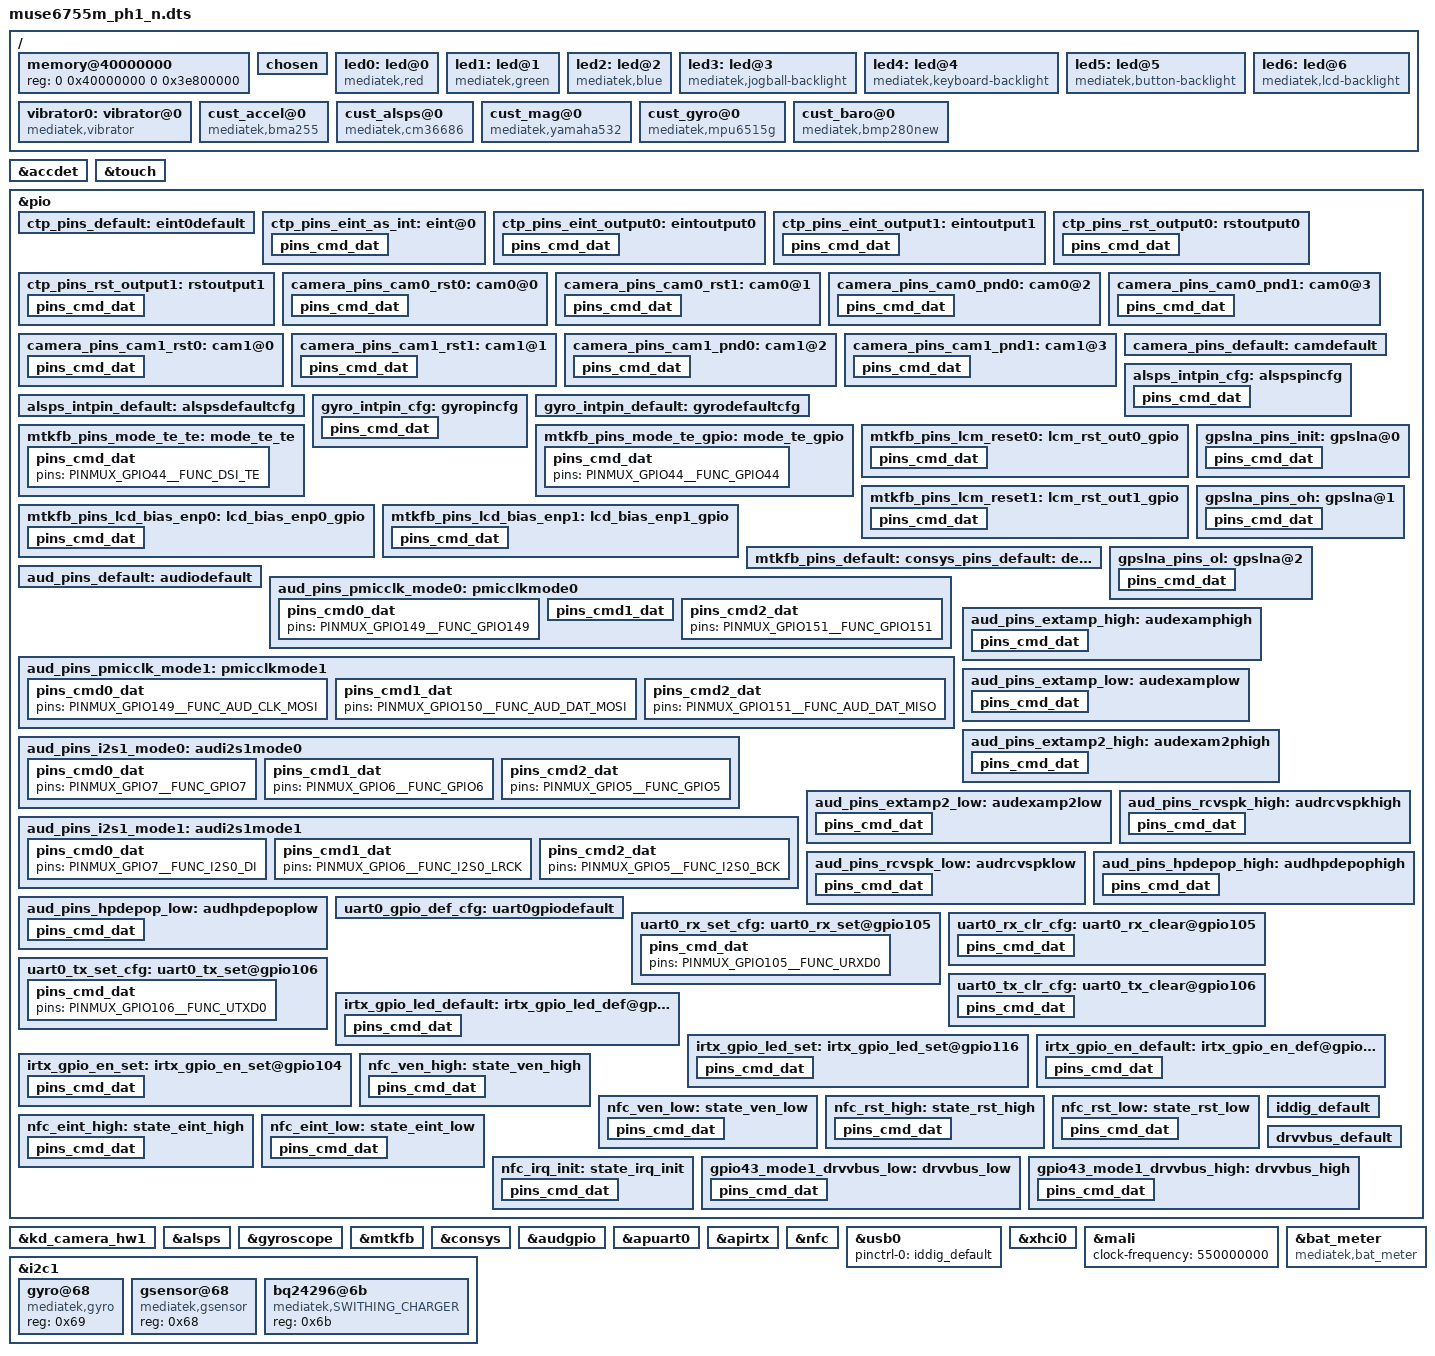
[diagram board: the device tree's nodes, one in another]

/dts-v1/;

#include "mt6755.dtsi"
#include "cust.dtsi"

/ {
	memory@40000000 {
		device_type = "memory";
		reg = <0 0x40000000 0 0x3e800000>;
	};
	/* chosen */
	chosen {
		bootargs = "console=tty0 console=ttyMT0,921600n1 root=/dev/ram initrd=0x44000000,0x4B434E loglevel=8";

		/* fpga may has no lk, we need to specify display info here */
		/* fb buffer is reserved using this dts by memory node above */
		atag,videolfb-fb_base_h = <0x0>;
		atag,videolfb-fb_base_l = <0x7E800000>;
		atag,videolfb-islcmfound = <1>;
		/* because no lk, so lcm is not inited */
		atag,videolfb-islcm_inited = <0>;
		atag,videolfb-fps= <6000>;
		atag,videolfb-vramSize= <0x01800000>;
		atag,videolfb-lcmname= "nt35695_fhd_dsi_cmd_truly_nt50358_drv";
	};
	led0:led@0 {
		compatible = "mediatek,red";
		led_mode = <0>;
		data = <1>;
		pwm_config = <0 0 0 0 0>;
	};
	led1:led@1 {
		compatible = "mediatek,green";
		led_mode = <0>;
		data = <1>;
		pwm_config = <0 0 0 0 0>;
	};
	led2:led@2 {
		compatible = "mediatek,blue";
		led_mode = <0>;
		data = <1>;
		pwm_config = <0 0 0 0 0>;
	};
	led3:led@3 {
		compatible = "mediatek,jogball-backlight";
		led_mode = <0>;
		data = <1>;
		pwm_config = <0 0 0 0 0>;
	};
	led4:led@4 {
		compatible = "mediatek,keyboard-backlight";
		led_mode = <0>;
		data = <1>;
		pwm_config = <0 0 0 0 0>;
	};
	led5:led@5 {
		compatible = "mediatek,button-backlight";
		led_mode = <0>;
		data = <1>;
		pwm_config = <0 0 0 0 0>;
	};
	led6:led@6 {
		compatible = "mediatek,lcd-backlight";
		led_mode = <4>;
		data = <1>;
		pwm_config = <0 0 0 0 0>;
	};
	vibrator0:vibrator@0 {
		compatible = "mediatek,vibrator";
		vib_timer = <25>;
		vib_limit = <9>;
		vib_vol= <5>;
	};
/*  start sensor */
	cust_accel@0 {
	compatible = "mediatek,bma255";
	reg = <0x11>;
	i2c_num	= <1>;
	i2c_addr = <0x11 0 0 0>;
	direction = <5>;
	power_id = <0xffff>;
	power_vol = <0>;
	firlen = <0>;
	is_batch_supported = <0>;
	};

	cust_alsps@0 {
		compatible		= "mediatek,cm36686";
		i2c_num			= <1>;
		i2c_addr		= <0x60 0 0 0>;
		polling_mode_ps		= <0>;
		polling_mode_als	= <1>;
		power_id		= <0xffff>;
		power_vol		= <0>;
/* Total has 15 level*/
		als_level	= <0 257 637 1027 2297 5588 6730 11301 20449 25768 31122 45552 57937 57937 57937>;
/*  Total has 16 range*/
		als_value	= <0 132 304 502 1004 2003 3006 5006 8004 10000 12000 16000 20000 20000 20000 20000>;
		ps_threshold_high	=  <70>;
		ps_threshold_low	=  <40>;
		is_batch_supported_ps	= <1>;
		is_batch_supported_als	= <1>;
	};

	cust_mag@0 {
	compatible			= "mediatek,yamaha532";
	i2c_num				= <1>;
	/* i2c_addr			= <0x0D 0 0 0>; */
	direction			= <0>;
	power_id			= <0xffff>;
	power_vol			= <0>;
	/* is_batch_supported		= <0>; */
	};

	cust_gyro@0 {
	compatible			= "mediatek,mpu6515g";
	i2c_num				= <1>;
	/* i2c_addr			= <0x68 0 0 0>; */
	direction			= <6>;
	power_id			= <0xffff>;
	power_vol			= <0>;
	firlen				= <0>;
	is_batch_supported		= <0>;
	};

	cust_baro@0 {
	compatible			= "mediatek,bmp280new";
	i2c_num				= <1>;
	/* i2c_addr			= <0x68 0 0 0>; */
	direction			= <0>;
	power_id			= <0xffff>;
	power_vol			= <0>;
	firlen				= <32>;
	is_batch_supported		= <0>;
	};
/* end sensor */
};
&accdet {
		accdet-mic-vol = <7>;
		headset-mode-setting = <0x500 0x500 1 0x3F0 0x800 0x800 0x200>;
		accdet-plugout-debounce = <20>;
		/*1:ACC mode, 2:low cost without in bias, 6:low cost with in bias*/
		accdet-mic-mode = <1>;
		/*0--MD_MAX--UP_MAX--DW_MAX*/
		headset-three-key-threshold = <0 80 220 500>;
		/*0--MD_MAX--VOICE_MAX--UP_MAX--DW_MAX*/
		headset-four-key-threshold = <0 58 121 192 450>;
};

/* TOUCH start */
&touch {
	tpd-resolution = <1080 1920>;
	use-tpd-button = <0>;
	tpd-key-num = <3>;
	tpd-key-local= <139 172 158 0>;
	tpd-key-dim-local = <90 883 100 40 230 883 100 40 370 883 100 40 0 0 0 0>;
	tpd-max-touch-num = <5>;
	tpd-filter-enable = <1>;
	tpd-filter-pixel-density = <146>;
	tpd-filter-custom-prameters = <0 0 0 0 0 0 0 0 0 0 0 0>;
	tpd-filter-custom-speed = <0 0 0>;
	pinctrl-names = "default", "state_eint_as_int", "state_eint_output0", "state_eint_output1",
		"state_rst_output0", "state_rst_output1";
	pinctrl-0 = <&ctp_pins_default>;
	pinctrl-1 = <&ctp_pins_eint_as_int>;
	pinctrl-2 = <&ctp_pins_eint_output0>;
	pinctrl-3 = <&ctp_pins_eint_output1>;
	pinctrl-4 = <&ctp_pins_rst_output0>;
	pinctrl-5 = <&ctp_pins_rst_output1>;
	status = "okay";
};
&pio {
	ctp_pins_default: eint0default {
	};
	ctp_pins_eint_as_int: eint@0 {
		pins_cmd_dat {
			pins = <PINMUX_GPIO1__FUNC_GPIO1>;
			slew-rate = <0>;
			bias-disable;
		};
	};
	ctp_pins_eint_output0: eintoutput0 {
		pins_cmd_dat {
			pins = <PINMUX_GPIO1__FUNC_GPIO1>;
			slew-rate = <1>;
			output-low;
		};
	};
	ctp_pins_eint_output1: eintoutput1 {
		pins_cmd_dat {
			pins = <PINMUX_GPIO1__FUNC_GPIO1>;
			slew-rate = <1>;
			output-high;
		};
	};
	ctp_pins_rst_output0: rstoutput0 {
		pins_cmd_dat {
			pins = <PINMUX_GPIO10__FUNC_GPIO10>;
			slew-rate = <1>;
			output-low;
		};
	};
	ctp_pins_rst_output1: rstoutput1 {
		pins_cmd_dat {
			pins = <PINMUX_GPIO10__FUNC_GPIO10>;
			slew-rate = <1>;
			output-high;
		};
	};
};
/* TOUCH end */

/* CAMERA GPIO standardization */
&pio {
	camera_pins_cam0_rst0: cam0@0 {
	    pins_cmd_dat {
			pins = <PINMUX_GPIO110__FUNC_GPIO110>;
			slew-rate = <1>; /*direction 0:in, 1:out*/
			output-low;/*direction out used only. output_low or high*/
		};
	};
	camera_pins_cam0_rst1: cam0@1 {
	    pins_cmd_dat {
			pins = <PINMUX_GPIO110__FUNC_GPIO110>;
			slew-rate = <1>;
			output-high;
		};
	};
	camera_pins_cam0_pnd0: cam0@2 {
	    pins_cmd_dat {
			pins = <PINMUX_GPIO107__FUNC_GPIO107>;
			slew-rate = <1>;
			output-low;
		};
	};
	camera_pins_cam0_pnd1: cam0@3 {
	    pins_cmd_dat {
			pins = <PINMUX_GPIO107__FUNC_GPIO107>;
			slew-rate = <1>;
			output-high;
		};
	};
	camera_pins_cam1_rst0: cam1@0 {
	    pins_cmd_dat {
			pins = <PINMUX_GPIO111__FUNC_GPIO111>;
			slew-rate = <1>; /*direction 0:in, 1:out*/
			output-low;/*direction out used only. output_low or high*/
		};
	};
	camera_pins_cam1_rst1: cam1@1 {
	    pins_cmd_dat {
			pins = <PINMUX_GPIO111__FUNC_GPIO111>;
			slew-rate = <1>;
			output-high;
		};
	};
	camera_pins_cam1_pnd0: cam1@2 {
	    pins_cmd_dat {
			pins = <PINMUX_GPIO108__FUNC_GPIO108>;
			slew-rate = <1>;
			output-low;
		};
	};
	camera_pins_cam1_pnd1: cam1@3 {
	    pins_cmd_dat {
			pins = <PINMUX_GPIO108__FUNC_GPIO108>;
			slew-rate = <1>;
			output-high;
		};
	};
	/*camera_pins_cam_ldo_vcama_0: cam@vcama0 {
	};
	camera_pins_cam_ldo_vcama_1: cam@vcama1 {
	};*/
	camera_pins_default: camdefault {
	};

};

&kd_camera_hw1 {
	pinctrl-names = "default",
			"cam0_rst0", "cam0_rst1", "cam0_pnd0", "cam0_pnd1",
			"cam1_rst0", "cam1_rst1", "cam1_pnd0", "cam1_pnd1";
			/*"cam2_rst0", "cam2_rst1", "cam2_pnd0", "cam2_pnd1",
			"cam_ldo_vcama_0", "cam_ldo_vcama_1";*/
	pinctrl-0 = <&camera_pins_default>;
	pinctrl-1 = <&camera_pins_cam0_rst0>;
	pinctrl-2 = <&camera_pins_cam0_rst1>;
	pinctrl-3 = <&camera_pins_cam0_pnd0>;
	pinctrl-4 = <&camera_pins_cam0_pnd1>;
	pinctrl-5 = <&camera_pins_cam1_rst0>;
	pinctrl-6 = <&camera_pins_cam1_rst1>;
	pinctrl-7 = <&camera_pins_cam1_pnd0>;
	pinctrl-8 = <&camera_pins_cam1_pnd1>;
	/* for main2 */
	/*pinctrl-9 = <&camera_pins_cam2_rst0>;
	pinctrl-10 = <&camera_pins_cam2_rst1>;
	pinctrl-11 = <&camera_pins_cam2_pnd0>;
	pinctrl-12 = <&camera_pins_cam2_pnd1>;*/
	/* for ldo control by gpio */
	/*pinctrl-13 = <&camera_pins_cam_ldo_vcama_0>;
	pinctrl-14 = <&camera_pins_cam_ldo_vcama_1>;*/
	status = "okay";

};
/* CAMERA GPIO end */

&pio {
	alsps_intpin_cfg: alspspincfg {

		pins_cmd_dat {
			pins = <PINMUX_GPIO6__FUNC_GPIO6>;
			slew-rate = <0>;
			bias-pull-up = <00>;
		};
	};

	alsps_intpin_default: alspsdefaultcfg {

	};

	gyro_intpin_cfg: gyropincfg {

		pins_cmd_dat {
			pins = <PINMUX_GPIO4__FUNC_GPIO4>;
			slew-rate = <0>;
			bias-pull-down = <00>;
		};
	};

	gyro_intpin_default: gyrodefaultcfg {

	};
};

&alsps {
	pinctrl-names = "pin_default", "pin_cfg";
	pinctrl-0 = <&alsps_intpin_default>;
	pinctrl-1 = <&alsps_intpin_cfg>;
	status = "okay";
};

&gyroscope {
	pinctrl-names = "pin_default", "pin_cfg";
	pinctrl-0 = <&gyro_intpin_default>;
	pinctrl-1 = <&gyro_intpin_cfg>;
	status = "okay";
};

/* DISPSYS GPIO standardization */
&pio {

	mtkfb_pins_mode_te_gpio: mode_te_gpio {
		pins_cmd_dat {
			pins = <PINMUX_GPIO44__FUNC_GPIO44>;
		};
	};

	mtkfb_pins_mode_te_te: mode_te_te {
		pins_cmd_dat {
			pins = <PINMUX_GPIO44__FUNC_DSI_TE>;
		};
	};

	mtkfb_pins_lcm_reset0: lcm_rst_out0_gpio {
		pins_cmd_dat {
			pins = <PINMUX_GPIO158__FUNC_LCM_RST>;
			slew-rate = <1>;
			output-low;
		};
	};

	mtkfb_pins_lcm_reset1: lcm_rst_out1_gpio {
		pins_cmd_dat {
			pins = <PINMUX_GPIO158__FUNC_LCM_RST>;
			slew-rate = <1>;
			output-high;
		};
	};

	mtkfb_pins_lcd_bias_enp0: lcd_bias_enp0_gpio {
		pins_cmd_dat {
			pins = <PINMUX_GPIO12__FUNC_GPIO12>;
			slew-rate = <1>;
			output-low;
		};
	};

	mtkfb_pins_lcd_bias_enp1: lcd_bias_enp1_gpio {
		pins_cmd_dat {
			pins = <PINMUX_GPIO12__FUNC_GPIO12>;
			slew-rate = <1>;
			output-high;
		};
	};

	mtkfb_pins_default: default {
	};
};

&mtkfb {
	pinctrl-names = "default", "mode_te_gpio", "mode_te_te", "lcm_rst_out0_gpio",
	"lcm_rst_out1_gpio", "lcd_bias_enp0_gpio", "lcd_bias_enp1_gpio";
	pinctrl-0 = <&mtkfb_pins_default>;
	pinctrl-1 = <&mtkfb_pins_mode_te_gpio>;
	pinctrl-2 = <&mtkfb_pins_mode_te_te>;
	pinctrl-3 = <&mtkfb_pins_lcm_reset0>;
	pinctrl-4 = <&mtkfb_pins_lcm_reset1>;
	pinctrl-5 = <&mtkfb_pins_lcd_bias_enp0>;
	pinctrl-6 = <&mtkfb_pins_lcd_bias_enp1>;
	status = "okay";
};/* DISPSYS GPIO standardization end */

/* CONSYS GPIO standardization */
&pio {
	consys_pins_default: default {
	};

	gpslna_pins_init: gpslna@0 {
		pins_cmd_dat {
			pins = <PINMUX_GPIO114__FUNC_GPIO114>;
			slew-rate = <0>;
			bias-disable;
			output-low;
		};
	};

	gpslna_pins_oh: gpslna@1 {
		pins_cmd_dat {
			pins = <PINMUX_GPIO114__FUNC_GPIO114>;
			slew-rate = <1>;
			output-high;
		};
	};

	gpslna_pins_ol: gpslna@2 {
		pins_cmd_dat {
			pins = <PINMUX_GPIO114__FUNC_GPIO114>;
			slew-rate = <1>;
			output-low;
		};
	};
};

&consys {
	pinctrl-names = "default", "gps_lna_state_init", "gps_lna_state_oh", "gps_lna_state_ol";
	pinctrl-0 = <&consys_pins_default>;
	pinctrl-1 = <&gpslna_pins_init>;
	pinctrl-2 = <&gpslna_pins_oh>;
	pinctrl-3 = <&gpslna_pins_ol>;
	status = "okay";
};
/* CONSYS end */

/* AUDIO GPIO standardization */
&audgpio {
	pinctrl-names = "default", "audpmicclk-mode0", "audpmicclk-mode1",
		"audi2s1-mode0", "audi2s1-mode1", "extamp-pullhigh", "extamp-pulllow",
		"extamp2-pullhigh", "extamp2-pulllow", "rcvspk-pullhigh",
		"rcvspk-pulllow","hpdepop-pullhigh","hpdepop-pulllow";
	pinctrl-0 = <&aud_pins_default>;
	pinctrl-1 = <&aud_pins_pmicclk_mode0>;
	pinctrl-2 = <&aud_pins_pmicclk_mode1>;
	pinctrl-3 = <&aud_pins_i2s1_mode0>;
	pinctrl-4 = <&aud_pins_i2s1_mode1>;
	pinctrl-5 = <&aud_pins_extamp_high>;
	pinctrl-6 = <&aud_pins_extamp_low>;
	pinctrl-7 = <&aud_pins_extamp2_high>;
	pinctrl-8 = <&aud_pins_extamp2_low>;
	pinctrl-9 = <&aud_pins_rcvspk_high>;
	pinctrl-10 = <&aud_pins_rcvspk_low>;
	pinctrl-11 = <&aud_pins_hpdepop_high>;
	pinctrl-12 = <&aud_pins_hpdepop_low>;
	status = "okay";
};

&pio {
	aud_pins_default: audiodefault {
	};

	aud_pins_pmicclk_mode0: pmicclkmode0 {
		pins_cmd0_dat {
			pins = <PINMUX_GPIO149__FUNC_GPIO149>;
		};
		pins_cmd1_dat {
			pins = <PINMUX_GPIO150__FUNC_GPIO150>;
			slew-rate = <0>;
			bias-pull-up = <00>;
		};
		pins_cmd2_dat {
			pins = <PINMUX_GPIO151__FUNC_GPIO151>;
		};
	};

	aud_pins_pmicclk_mode1: pmicclkmode1 {
		pins_cmd0_dat {
			pins = <PINMUX_GPIO149__FUNC_AUD_CLK_MOSI>;
		};
		pins_cmd1_dat {
			pins = <PINMUX_GPIO150__FUNC_AUD_DAT_MOSI>;
		};
		pins_cmd2_dat {
			pins = <PINMUX_GPIO151__FUNC_AUD_DAT_MISO>;
		};
	};

	aud_pins_i2s1_mode0: audi2s1mode0 {
		pins_cmd0_dat {
			pins = <PINMUX_GPIO7__FUNC_GPIO7>;
		};
		pins_cmd1_dat {
			pins = <PINMUX_GPIO6__FUNC_GPIO6>;
		};
		pins_cmd2_dat {
			pins = <PINMUX_GPIO5__FUNC_GPIO5>;
		};
	};

	aud_pins_i2s1_mode1: audi2s1mode1 {
		pins_cmd0_dat {
			pins = <PINMUX_GPIO7__FUNC_I2S0_DI>;
		};
		pins_cmd1_dat {
			pins = <PINMUX_GPIO6__FUNC_I2S0_LRCK>;
		};
		pins_cmd2_dat {
			pins = <PINMUX_GPIO5__FUNC_I2S0_BCK>;
		};
	};

	aud_pins_extamp_high: audexamphigh {
		pins_cmd_dat {
			pins = <PINMUX_GPIO115__FUNC_GPIO115>;
			slew-rate = <1>;
			output-high;
		};
	};

	aud_pins_extamp_low: audexamplow {
		pins_cmd_dat {
			pins = <PINMUX_GPIO115__FUNC_GPIO115>;
			slew-rate = <1>;
			output-low;
		};
	};

	aud_pins_extamp2_high: audexam2phigh {
		pins_cmd_dat {
			pins = <PINMUX_GPIO54__FUNC_GPIO54>;
			slew-rate = <1>;
			output-high;
		};
	};
	aud_pins_extamp2_low: audexamp2low {
		pins_cmd_dat {
			pins = <PINMUX_GPIO54__FUNC_GPIO54>;
			slew-rate = <1>;
			output-low;
		};
	};

	aud_pins_rcvspk_high: audrcvspkhigh {
		pins_cmd_dat {
			pins = <PINMUX_GPIO120__FUNC_GPIO120>;
			slew-rate = <1>;
			output-high;
		};
	};

	aud_pins_rcvspk_low: audrcvspklow {
		pins_cmd_dat {
			pins = <PINMUX_GPIO120__FUNC_GPIO120>;
			slew-rate = <1>;
			output-low;
		};
	};

	aud_pins_hpdepop_high: audhpdepophigh {
		pins_cmd_dat {
			pins = <PINMUX_GPIO24__FUNC_GPIO24>;
			slew-rate = <1>;
			output-high;
		};
	};

	aud_pins_hpdepop_low: audhpdepoplow {
		pins_cmd_dat {
			pins = <PINMUX_GPIO24__FUNC_GPIO24>;
			slew-rate = <1>;
			output-low;
		};
	};
};
/* AUDIO end */

/* UART GPIO */
&apuart0 {
	pinctrl-names = "uart0_gpio_default",
			"uart0_rx_set",
			"uart0_rx_clear",
			"uart0_tx_set",
			"uart0_tx_clear";
	pinctrl-0 = <&uart0_gpio_def_cfg>;
	pinctrl-1 = <&uart0_rx_set_cfg>;
	pinctrl-2 = <&uart0_rx_clr_cfg>;
	pinctrl-3 = <&uart0_tx_set_cfg>;
	pinctrl-4 = <&uart0_tx_clr_cfg>;
	status = "okay";
};

&pio {
	/* UART GPIO Settings - Start */
	/* UART0: rx set, rx clear, tx clear, tx clear*/
	uart0_gpio_def_cfg:uart0gpiodefault {

	};
	uart0_rx_set_cfg:uart0_rx_set@gpio105 {
		pins_cmd_dat {
			pins = <PINMUX_GPIO105__FUNC_URXD0>;
		};
	};
	uart0_rx_clr_cfg:uart0_rx_clear@gpio105  {
		pins_cmd_dat {
			pins = <PINMUX_GPIO105__FUNC_GPIO105>;
			slew-rate = <1>;
			output-high;
		};
	};
	uart0_tx_set_cfg:uart0_tx_set@gpio106  {
		pins_cmd_dat {
			pins = <PINMUX_GPIO106__FUNC_UTXD0>;
		};
	};
	uart0_tx_clr_cfg:uart0_tx_clear@gpio106  {
		pins_cmd_dat {
			pins = <PINMUX_GPIO106__FUNC_GPIO106>;
			slew-rate = <1>;
			output-high;
		};
	};
};/* UART GPIO end */

/* IRTX GPIO end */
&apirtx {
	pinctrl-names = "irtx_gpio_led_default",
			"irtx_gpio_led_set",
			"irtx_gpio_en_default",
			"irtx_gpio_en_set";

	pinctrl-0 = <&irtx_gpio_led_default>;
	pinctrl-1 = <&irtx_gpio_led_set>;
	pinctrl-2 = <&irtx_gpio_en_default>;
	pinctrl-3 = <&irtx_gpio_en_set>;
	status = "okay";
};
&pio {
	/* IRTX GPIO Settings -Start */
	/* default: GPIO0, output, high */
	irtx_gpio_led_default:irtx_gpio_led_def@gpio116 {
		pins_cmd_dat {
			pins = <PINMUX_GPIO116__FUNC_GPIO116>;
			slew-rate = <1>;
			bias-disable;
			output-low;
			input-schmitt-enable = <0>;
		};
	};

	irtx_gpio_led_set:irtx_gpio_led_set@gpio116 {
		pins_cmd_dat {
			pins = <PINMUX_GPIO116__FUNC_GPIO116>;
			slew-rate = <1>;
			output-high;
		};
	};

	irtx_gpio_en_default:irtx_gpio_en_def@gpio104 {
		pins_cmd_dat {
			pins = <PINMUX_GPIO104__FUNC_GPIO104>;
			slew-rate = <1>;
			bias-disable;
			output-low;
			input-schmitt-enable = <0>;
		};
	};

	irtx_gpio_en_set:irtx_gpio_en_set@gpio104 {
		pins_cmd_dat {
			pins = <PINMUX_GPIO104__FUNC_GPIO104>;
			slew-rate = <1>;
			output-high;
		};
	};


}; /* IRTX GPIO Settings -End */

/* NFC GPIO standardization */
&pio {
	nfc_default: default {

	};

	nfc_ven_high: state_ven_high {
		pins_cmd_dat {
			pins = <PINMUX_GPIO28__FUNC_GPIO28>;
			slew-rate = <1>;
			output-high;
		};
	};

	nfc_ven_low: state_ven_low {
		pins_cmd_dat {
			pins = <PINMUX_GPIO28__FUNC_GPIO28>;
			slew-rate = <1>;
			output-low;
		};
	};

	nfc_rst_high: state_rst_high {
		pins_cmd_dat {
			pins = <PINMUX_GPIO25__FUNC_GPIO25>;
			slew-rate = <1>;
			output-high;
		};
	};

	nfc_rst_low: state_rst_low {
		pins_cmd_dat {
			pins = <PINMUX_GPIO25__FUNC_GPIO25>;
			slew-rate = <1>;
			output-low;
		};
	};

	nfc_eint_high: state_eint_high {
		pins_cmd_dat {
			pins = <PINMUX_GPIO27__FUNC_GPIO27>;
			slew-rate = <1>;
			output-high;
		};
	};

	nfc_eint_low: state_eint_low {
		pins_cmd_dat {
			pins = <PINMUX_GPIO27__FUNC_GPIO27>;
			slew-rate = <1>;
			output-low;
		};
	};

	nfc_irq_init: state_irq_init {
		pins_cmd_dat {
			pins = <PINMUX_GPIO26__FUNC_GPIO26>;
			slew-rate = <0>;
			bias-pull-down = <00>;
		};
	};
};

&nfc {
	pinctrl-names = "default", "ven_high", "ven_low", "rst_high", "rst_low", "eint_high", "eint_low", "irq_init";
	pinctrl-0 = <&nfc_default>;
	pinctrl-1 = <&nfc_ven_high>;
	pinctrl-2 = <&nfc_ven_low>;
	pinctrl-3 = <&nfc_rst_high>;
	pinctrl-4 = <&nfc_rst_low>;
	pinctrl-5 = <&nfc_eint_high>;
	pinctrl-6 = <&nfc_eint_low>;
	pinctrl-7 = <&nfc_irq_init>;
	status = "okay";
};
/* NFC end */




&pio {
	iddig_default: iddig_default {
	};

/*
	gpio42_mode1_iddig: iddig_init {
		pins_cmd_dat {
			pins = <PINMUX_GPIO42__FUNC_IDDIG>;
			slew-rate = <0>;
			bias-pull-up = <00>;
		};
	};
*/
};

&pio {
	drvvbus_default: drvvbus_default {
	};

	gpio43_mode1_drvvbus_low: drvvbus_low {
		pins_cmd_dat {
			pins = <PINMUX_GPIO43__FUNC_USB_DRVVBUS>;
			slew-rate = <1>;
			output-low;
		};
	};

	gpio43_mode1_drvvbus_high: drvvbus_high {
		pins_cmd_dat {
			pins = <PINMUX_GPIO43__FUNC_USB_DRVVBUS>;
			slew-rate = <1>;
			output-high;
		};
	};
};

&usb0 {
	pinctrl-names = "iddig_default", "iddig_init";
	pinctrl-0 = <&iddig_default>;
/*	pinctrl-1 = <&gpio42_mode1_iddig>; */
	status = "okay";
};

&xhci0 {
	pinctrl-names = "drvvbus_default", "drvvbus_low", "drvvbus_high";
	pinctrl-0 = <&drvvbus_default>;
	pinctrl-1 = <&gpio43_mode1_drvvbus_low>;
	pinctrl-2 = <&gpio43_mode1_drvvbus_high>;
	status = "okay";
};

&i2c1 {

	gyro@68 {
		compatible = "mediatek,gyro";
		reg = <0x69>;
		status = "okay";
	};

	gsensor@68 {
		compatible = "mediatek,gsensor";
		reg = <0x68>;
		status = "okay";
	};

	bq24296@6b {
		compatible = "mediatek,SWITHING_CHARGER";
		reg = <0x6b>;
		status = "okay";
	};
};

&mali {
	clock-frequency = <550000000>;
};

&bat_meter {
compatible = "mediatek,bat_meter";
/* cust_charging.h */
/* stop charging while in talking mode */
stop_charging_in_takling = <1 >;
talking_recharge_voltage = <3800 >;
talking_sync_time = <60 >;

/* Battery Temperature Protection */
mtk_temperature_recharge_support = <1 >;
max_charge_temperature = <50 >;
max_charge_temperature_minus_x_degree = <47 >;
min_charge_temperature = <0 >;
min_charge_temperature_plus_x_degree = <6 >;
err_charge_temperature = <0xff >;

/* Linear Charging Threshold */
v_pre2cc_thres = <3400 >;	/* unit: mV */
v_cc2topoff_thres = <4050 >;
recharging_voltage = <4110 >;
charging_full_current = <100 >;	/* unit: mA */

/* Charging Current Setting */
config_usb_if = <0 >;
usb_charger_current_suspend = <0 >;	/* Unit: 0.01 mA */
usb_charger_current_unconfigured = <7000 >;	/* Unit: 0.01 mA */
usb_charger_current_configured = <50000 >;	/* Unit: 0.01 mA */
usb_charger_current = <50000 >;	/* Unit: 0.01 mA */
ac_charger_current = <80000 >;	/* Unit: 0.01 mA */
non_std_ac_charger_current = <50000 >;	/* Unit: 0.01 mA */
charging_host_charger_current = <65000 >;	/* Unit: 0.01 mA */
apple_0_5a_charger_current = <50000 >;	/* Unit: 0.01 mA */
apple_1_0a_charger_current = <65000 >;	/* Unit: 0.01 mA */
apple_2_1a_charger_current = <80000 >;	/* Unit: 0.01 mA */


/* charger error check */
bat_low_temp_protect_enable = <0 >;
v_charger_enable = <0 >;	/* 1:on , 0:off */
v_charger_max = <6500 >;	/* unit: mV */
v_charger_min = <4400 >;

/*  Tracking TIME */
onehundred_percent_tracking_time = <10 >;	/* Unit: second */
npercent_tracking_time = <20 >;	/* Unit: second */
sync_to_real_tracking_time = <60 >;	/* Unit: second */
v_0percent_tracking = <3450 >;	/* Unit: mV */

/* High battery support */
high_battery_voltage_support = <0 >;

/* cust_battery_meter.h */
hw_fg_force_use_sw_ocv = <0 >;
/* ADC resistor  */
r_bat_sense = <4 >;
r_i_sense = <4 >;
r_charger_1 = <330 >;
r_charger_2 = <39 >;
temperature_t0 = <110 >;
temperature_t1 = <0 >;
temperature_t2 = <25 >;
temperature_t3 = <50 >;
temperature_t = <255 >;	/* this should be fixed, never change the value */
fg_meter_resistance = <0 >;

/* Qmax for 0mA */
q_max_pos_50 = <3003 >;
q_max_pos_25 = <2838 >;
q_max_pos_0 = <2723 >;
q_max_neg_10 = <2498 >;
/* Qmax for 400mA, said high current */
q_max_pos_50_h_current = <2991 >;
q_max_pos_25_h_current = <2818 >;
q_max_pos_0_h_current = <2476 >;
q_max_neg_10_h_current = <1633 >;
/* Discharge percentage, 1: D5, 0: D2 */
oam_d5 = <1 >;

change_tracking_point = <1 >;
/* SW OCV tracking setting */
cust_tracking_point = <0 >;
cust_r_sense = <56 >;
cust_hw_cc = <0 >;
aging_tuning_value = <103 >;
cust_r_fg_offset = <0 >;
ocv_board_compesate = <0 >;
r_fg_board_base = <1000 >;
r_fg_board_slope = <1000 >;
car_tune_value = <100 >;

/* HW Fuel gague  */
current_detect_r_fg = <10 >;	/* Unit: mA */
minerroroffset = <1000 >;
fg_vbat_average_size = <18 >;
r_fg_value = <10 >;	/* Unit: mOhm */

/* HW Fuel gague 2.0*/
difference_hwocv_rtc = <30 >;
difference_hwocv_swocv = <10>;
difference_swocv_rtc = <10>;

difference_hwocv_vbat = <30>;
difference_vbat_rtc = <30>;
difference_swocv_rtc_pos = <15>;

max_swocv = <3>;

difference_voltage_update = <20>;
aging1_load_soc = <70>;
aging1_update_soc = <30>;
batterypseudo100 = <95>;
batterypseudo1 = <6>;

q_max_by_sys = <1>;			/*8. qmax variant by system drop voltage.*/
q_max_sys_voltage = <3350>;
shutdown_gauge0 = <0>;
shutdown_gauge1_xmins = <0>;
shutdown_gauge1_mins = <60>;

shutdown_system_voltage = <3400>;
charge_tracking_time = <60>;
discharge_tracking_time = <10>;

recharge_tolerance = <10>;

/* SW Fuel Gauge */
max_hwocv = <5 >;
max_vbat = <90 >;



/* HW Fuel gague 1.0*/
cust_poweron_delta_capacity_tolrance = <40 >;
cust_poweron_low_capacity_tolrance = <5 >;
cust_poweron_max_vbat_tolrance = <90 >;
cust_poweron_delta_vbat_tolrance = <30 >;
cust_poweron_delta_hw_sw_ocv_capacity_tolrance = <10 >;

/* Fixed battery temperature */
fixed_tbat_25 = <0 >;
/* Dynamic change wake up period of battery thread when suspend */
vbat_normal_wakeup = <3600 >;	/* Unit: mV */
vbat_low_power_wakeup = <3500 >;	/* Unit: mV */
normal_wakeup_period = <5400 >;	/* Unit: second */
low_power_wakeup_period = <300 >;	/* Unit: second */
close_poweroff_wakeup_period = <30 >;	/* Unit: second */

init_soc_by_sw_soc = <1 >;
sync_ui_soc_imm =<0>;
mtk_enable_aging_algorithm = <1>;
md_sleep_current_check = <1>;
q_max_by_current = <0>;

/* SOC track to SWOCV */
cust_tracking_gap = <15 >;	/* start tracking gap */
cust_trackingoffset = <0 >;	/* force offset to shift soc to 0 */
cust_trackingen = <0 >;	/* 0:disable, 1:enable */

/* keep min uisoc until voltage less than shutdown voltage */
cust_min_uisoc_percentage = <1 >;

rbat_pull_up_r = <62000 >;
rbat_pull_up_volt = <1800 >;

batt_temperature_table_size = <17 >;
batt_temperature_table = <
	(-20) 738931
	(-15) 547472
	(-10) 409600
	(-5) 309299
	0 235622
	5 181001
	10 140153
	15 109349
	20 85934
	25 68000 30 54165 35 43418 40 35014 45 28400 50 23164 55 17733 60 15656 >;

/* PH1_ZCV Table_ EAC63158401 4.4 V 3000mAH  V1.0_cut off 3.3V */
battery_profile_t0_size = <69 >;
battery_profile_t0 = <0 4357
	2 4329
	4 4304
	6 4280
	8 4258
	10 4236
	12 4214
	14 4192
	16 4170
	18 4148
	20 4124
	22 4099
	24 4075
	26 4052
	28 4032
	30 4012
	32 3992
	34 3972
	36 3954
	38 3936
	40 3916
	42 3898
	44 3879
	46 3864
	48 3849
	50 3837
	52 3827
	54 3819
	56 3811
	58 3804
	60 3799
	62 3795
	64 3790
	66 3788
	68 3783
	70 3779
	72 3773
	74 3767
	76 3759
	78 3750
	80 3740
	82 3729
	84 3718
	86 3707
	88 3697
	90 3687
	92 3675
	94 3658
	96 3631
	97 3614
	97 3603
	98 3592
	98 3582
	99 3572
	99 3561
	99 3549
	99 3539
	100 3528
	100 3518
	100 3509
	100 3509
	100 3509
	100 3509
	100 3509
	100 3509
	100 3509
	100 3509
	100 3509
	100 3300 >;
battery_profile_t1_size = <69 >;
battery_profile_t1 = <0 4384
	2 4358
	4 4332
	5 4300
	7 4269
	9 4240
	11 4213
	13 4187
	15 4164
	16 4141
	18 4118
	20 4098
	22 4077
	24 4058
	26 4038
	27 4019
	29 4000
	31 3984
	33 3968
	35 3952
	37 3934
	38 3916
	40 3898
	42 3881
	44 3867
	46 3855
	48 3845
	49 3836
	51 3828
	53 3820
	55 3813
	57 3807
	59 3800
	60 3794
	62 3790
	64 3786
	66 3782
	68 3779
	70 3775
	71 3771
	73 3766
	75 3760
	77 3753
	79 3745
	80 3735
	82 3723
	84 3711
	86 3700
	88 3692
	90 3685
	91 3676
	93 3666
	95 3642
	97 3586
	98 3540
	98 3512
	99 3488
	99 3468
	99 3451
	99 3435
	99 3421
	99 3408
	100 3396
	100 3386
	100 3375
	100 3366
	100 3357
	100 3348
	100 3300 >;
battery_profile_t2_size = <69 >;
battery_profile_t2 = <0 4392
	2 4372
	4 4355
	5 4336
	7 4317
	9 4297
	11 4278
	12 4258
	14 4239
	16 4218
	18 4198
	19 4178
	21 4158
	23 4139
	25 4120
	26 4101
	28 4084
	30 4067
	32 4049
	33 4032
	35 4015
	37 3999
	39 3982
	40 3965
	42 3944
	44 3923
	46 3905
	47 3890
	49 3878
	51 3868
	53 3857
	54 3849
	56 3839
	58 3831
	60 3824
	62 3817
	63 3810
	65 3804
	67 3798
	69 3792
	70 3787
	72 3781
	74 3775
	76 3771
	77 3762
	79 3753
	81 3745
	83 3733
	84 3719
	86 3703
	88 3692
	90 3689
	91 3688
	93 3686
	95 3680
	97 3622
	98 3509
	100 3279
	100 3058
	100 3005
	100 2983
	100 2968
	100 2956
	100 2950
	100 2941
	100 2941
	100 2938
	100 2933
	100 3400 >;
battery_profile_t3_size = <69 >;
battery_profile_t3 = <0 4395
	2 4373
	3 4355
	5 4337
	7 4318
	8 4299
	10 4279
	12 4260
	13 4239
	15 4220
	17 4200
	18 4180
	20 4161
	22 4142
	23 4123
	25 4105
	27 4087
	28 4070
	30 4052
	32 4036
	33 4020
	35 4004
	36 3990
	38 3976
	40 3963
	41 3949
	43 3936
	45 3920
	46 3896
	48 3877
	50 3865
	51 3854
	53 3845
	55 3836
	56 3828
	58 3821
	60 3814
	61 3807
	63 3802
	65 3796
	66 3790
	68 3786
	70 3782
	71 3775
	73 3765
	75 3755
	76 3749
	78 3742
	80 3734
	81 3728
	83 3720
	85 3705
	86 3693
	88 3676
	90 3675
	91 3673
	93 3670
	95 3667
	96 3628
	98 3536
	100 3382
	100 3108
	100 3060
	100 3034
	100 3013
	100 2998
	100 2983
	100 2972
	100 3400 >;

r_profile_t0_size = <69 >;
r_profile_t0 = <618 4357
	618 4329
	640 4304
	650 4280
	663 4258
	670 4236
	678 4214
	688 4192
	693 4170
	708 4148
	725 4124
	753 4099
	788 4075
	823 4052
	860 4032
	898 4012
	935 3992
	975 3972
	1025 3954
	1068 3936
	1108 3916
	1148 3898
	1153 3879
	1155 3864
	1153 3849
	1153 3837
	1158 3827
	1165 3819
	1165 3811
	1175 3804
	1183 3799
	1198 3795
	1208 3790
	1225 3788
	1240 3783
	1265 3779
	1288 3773
	1313 3767
	1335 3759
	1363 3750
	1395 3740
	1433 3729
	1475 3718
	1533 3707
	1598 3697
	1678 3687
	1773 3675
	1890 3658
	2025 3631
	2038 3614
	2010 3603
	1983 3592
	1958 3582
	1933 3572
	1910 3561
	1880 3549
	1850 3539
	1825 3528
	1803 3518
	1778 3509
	1778 3509
	1778 3509
	1778 3509
	1778 3509
	1778 3509
	1778 3509
	1778 3509
	1778 3509
	1255 3300 >;
r_profile_t1_size = <69 >;
r_profile_t1 = <300 4384
	300 4358
	313 4332
	325 4300
	350 4269
	375 4240
	395 4213
	420 4187
	443 4164
	465 4141
	485 4118
	510 4098
	530 4077
	553 4058
	565 4038
	578 4019
	583 4000
	593 3984
	593 3968
	595 3952
	585 3934
	583 3916
	573 3898
	563 3881
	563 3867
	563 3855
	568 3845
	568 3836
	570 3828
	578 3820
	580 3813
	588 3807
	588 3800
	595 3794
	600 3790
	605 3786
	613 3782
	620 3779
	628 3775
	638 3771
	648 3766
	660 3760
	673	3753
	688	3745
	705 3735
	723 3723
	745 3711
	775 3700
	813 3692
	880 3685
	975 3676
	1120 3666
	1345 3642
	1705 3586
	1853 3540
	1783 3512
	1725 3488
	1680 3468
	1630 3451
	1610 3435
	1570 3421
	1545 3408
	1495 3396
	1483 3386
	1440 3375
	1425 3366
	1393 3357
	1395 3348
	1290 3300 >;
r_profile_t2_size = <69 >;
r_profile_t2 = <155 4392
	155 4372
	158 4355
	158 4336
	158 4317
	155 4297
	160 4278
	163 4258
	165 4239
	168 4218
	170 4198
	170 4178
	170 4158
	175 4139
	175 4120
	178 4101
	185 4084
	190 4067
	193 4049
	195 4032
	200 4015
	205 3999
	208 3982
	203 3965
	193 3944
	178 3923
	168 3905
	160 3890
	160 3878
	160 3868
	158 3857
	163 3849
	160 3839
	160 3831
	163 3824
	165 3817
	163 3810
	168 3804
	168 3798
	170 3792
	173 3787
	170 3781
	170 3775
	175 3771
	168 3762
	165 3753
	168 3745
	165 3733
	163 3719
	163 3703
	160 3692
	160 3689
	170 3688
	180 3686
	205 3680
	188 3622
	203 3509
	255 3279
	658 3058
	530 3005
	475 2983
	428 2968
	423 2956
	400 2950
	405 2941
	363 2941
	348 2938
	335 2933
	370 3400 >;
r_profile_t3_size = <69 >;
r_profile_t3 = <73 4395
	73 4373
	78 4355
	78 4337
	80 4318
	78 4299
	78 4279
	80 4260
	80 4239
	83 4220
	83 4200
	83 4180
	85 4161
	88 4142
	88 4123
	88 4105
	90 4087
	93 4070
	93 4052
	95 4036
	98 4020
	98 4004
	103 3990
	108 3976
	113 3963
	118 3949
	123 3936
	128 3920
	100 3896
	85 3877
	83 3865
	83 3854
	83 3845
	80 3836
	85 3828
	88 3821
	88 3814
	88 3807
	90 3802
	93 3796
	93 3790
	95 3786
	100 3782
	98 3775
	88 3765
	85 3755
	83 3749
	85 3742
	83 3734
	85 3728
	88 3720
	83 3705
	85 3693
	83 3676
	88 3675
	88 3673
	90 3670
	100 3667
	95 3628
	108 3536
	138 3382
	773 3108
	658 3060
	585 3034
	550 3013
	503 2998
	470 2983
	453 2972
	438 3400 >;
};

